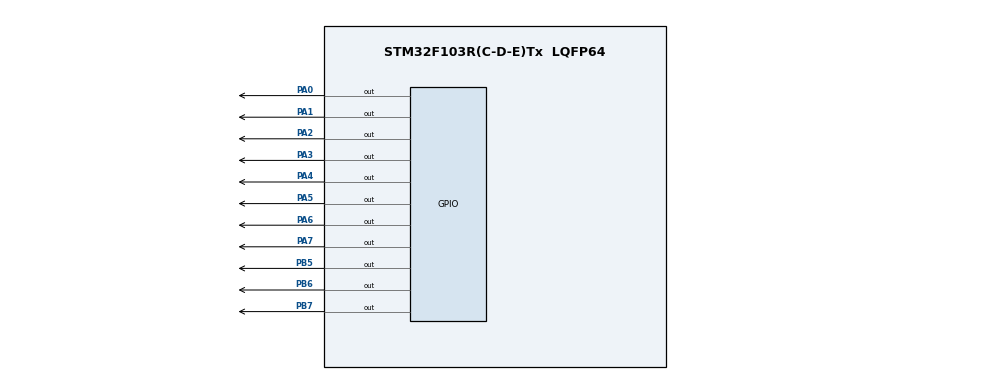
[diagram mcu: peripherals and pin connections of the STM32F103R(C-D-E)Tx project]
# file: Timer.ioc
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Mcu.Family=STM32F1
Mcu.Name=STM32F103R(C-D-E)Tx
Mcu.Package=LQFP64
NVIC.PriorityGroup=NVIC_PRIORITYGROUP_4
NVIC.TIM1_UP_IRQn=true\:1\:0\:true
NVIC.TIM6_IRQn=true\:2\:0\:true
PA0-WKUP.Signal=GPIO_Output
PA1.Signal=GPIO_Output
PA2.Signal=GPIO_Output
PA3.Signal=GPIO_Output
PA4.Signal=GPIO_Output
PA5.Signal=GPIO_Output
PA6.Signal=GPIO_Output
PA7.Signal=GPIO_Output
PB5.Signal=GPIO_Output
PB6.Signal=GPIO_Output
PB7.Signal=GPIO_Output
PD0-OSC_IN.Mode=HSE-External-Oscillator
PD0-OSC_IN.Signal=RCC_OSC_IN
PD1-OSC_OUT.Mode=HSE-External-Oscillator
PD1-OSC_OUT.Signal=RCC_OSC_OUT
ProjectManager.TargetToolchain=EWARM
RCC.APB1Freq_Value=8000000
RCC.APB2Freq_Value=8000000
RCC.SYSCLKSource=RCC_SYSCLKSOURCE_HSE
TIM1.CounterMode=TIM_COUNTERMODE_UP
TIM1.Period=249
TIM1.Prescaler=7999
TIM6.Period=999
TIM6.Prescaler=7999
VP_TIM1_VS_ClockSourceINT.Mode=Internal
VP_TIM6_VS_ClockSourceINT.Mode=Enable_Timer
board=Timer

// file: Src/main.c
/**
  ******************************************************************************
  * File Name          : main.c
  * Description        : Main program body
  ******************************************************************************
  *
  * COPYRIGHT(c) 2016 STMicroelectronics
  *
  * Redistribution and use in source and binary forms, with or without modification,
  * are permitted provided that the following conditions are met:
  *   1. Redistributions of source code must retain the above copyright notice,
  *      this list of conditions and the following disclaimer.
  *   2. Redistributions in binary form must reproduce the above copyright notice,
  *      this list of conditions and the following disclaimer in the documentation
  *      and/or other materials provided with the distribution.
  *   3. Neither the name of STMicroelectronics nor the names of its contributors
  *      may be used to endorse or promote products derived from this software
  *      without specific prior written permission.
  *
  * THIS SOFTWARE IS PROVIDED BY THE COPYRIGHT HOLDERS AND CONTRIBUTORS "AS IS"
  * AND ANY EXPRESS OR IMPLIED WARRANTIES, INCLUDING, BUT NOT LIMITED TO, THE
  * IMPLIED WARRANTIES OF MERCHANTABILITY AND FITNESS FOR A PARTICULAR PURPOSE ARE
  * DISCLAIMED. IN NO EVENT SHALL THE COPYRIGHT HOLDER OR CONTRIBUTORS BE LIABLE
  * FOR ANY DIRECT, INDIRECT, INCIDENTAL, SPECIAL, EXEMPLARY, OR CONSEQUENTIAL
  * DAMAGES (INCLUDING, BUT NOT LIMITED TO, PROCUREMENT OF SUBSTITUTE GOODS OR
  * SERVICES; LOSS OF USE, DATA, OR PROFITS; OR BUSINESS INTERRUPTION) HOWEVER
  * CAUSED AND ON ANY THEORY OF LIABILITY, WHETHER IN CONTRACT, STRICT LIABILITY,
  * OR TORT (INCLUDING NEGLIGENCE OR OTHERWISE) ARISING IN ANY WAY OUT OF THE USE
  * OF THIS SOFTWARE, EVEN IF ADVISED OF THE POSSIBILITY OF SUCH DAMAGE.
  *
  ******************************************************************************
  */
#include "stm32f1xx_hal.h"

/* USER CODE BEGIN Includes */

#include "LCD\lcd.h"
#include <stdio.h>

/* USER CODE END Includes */

TIM_HandleTypeDef htim1;
TIM_HandleTypeDef htim6;

/* USER CODE BEGIN PV */
/* Private variables ---------------------------------------------------------*/

int i,j;
char str[17];

/* USER CODE END PV */

void SystemClock_Config(void);
static void MX_GPIO_Init(void);
static void MX_TIM1_Init(void);
static void MX_TIM6_Init(void);

/* USER CODE BEGIN PFP */
/* Private function prototypes -----------------------------------------------*/

/* USER CODE END PFP */

int main(void)
{

  /* MCU Configuration----------------------------------------------------------*/

  /* Reset of all peripherals, Initializes the Flash interface and the Systick. */
  HAL_Init();

  /* Configure the system clock */
  SystemClock_Config();

  /* Initialize all configured peripherals */
  MX_GPIO_Init();
  MX_TIM1_Init();
  MX_TIM6_Init();

  /* USER CODE BEGIN 2 */

   HAL_TIM_Base_Start_IT(&htim1);
   HAL_TIM_Base_Start_IT(&htim6);

   lcd_init();
   lcd_clear();

  /* USER CODE END 2 */

  /* Infinite loop */
  /* USER CODE BEGIN WHILE */
  while (1)
  {
    sprintf(str,"Timer1=%d",i);

    lcd_gotoxy(0,0);
    lcd_puts(str);

    sprintf(str,"Timer2=%d",j);

    lcd_gotoxy(0,1);
    lcd_puts(str);

  /* USER CODE END WHILE */

  }

}

/** System Clock Configuration
*/
void SystemClock_Config(void)
{

  RCC_OscInitTypeDef RCC_OscInitStruct;
  RCC_ClkInitTypeDef RCC_ClkInitStruct;

  RCC_OscInitStruct.OscillatorType = RCC_OSCILLATORTYPE_HSE;
  RCC_OscInitStruct.HSEState = RCC_HSE_ON;
  RCC_OscInitStruct.PLL.PLLState = RCC_PLL_NONE;
  HAL_RCC_OscConfig(&RCC_OscInitStruct);

  RCC_ClkInitStruct.ClockType = RCC_CLOCKTYPE_SYSCLK;
  RCC_ClkInitStruct.SYSCLKSource = RCC_SYSCLKSOURCE_HSE;
  RCC_ClkInitStruct.AHBCLKDivider = RCC_SYSCLK_DIV1;
  RCC_ClkInitStruct.APB1CLKDivider = RCC_HCLK_DIV1;
  RCC_ClkInitStruct.APB2CLKDivider = RCC_HCLK_DIV1;
  HAL_RCC_ClockConfig(&RCC_ClkInitStruct, FLASH_LATENCY_0);

  HAL_SYSTICK_Config(HAL_RCC_GetHCLKFreq()/1000);

  HAL_SYSTICK_CLKSourceConfig(SYSTICK_CLKSOURCE_HCLK);

  /* SysTick_IRQn interrupt configuration */
  HAL_NVIC_SetPriority(SysTick_IRQn, 0, 0);
}

/* TIM1 init function */
void MX_TIM1_Init(void)
{

  TIM_ClockConfigTypeDef sClockSourceConfig;
  TIM_MasterConfigTypeDef sMasterConfig;

  htim1.Instance = TIM1;
  htim1.Init.Prescaler = 7999;
  htim1.Init.CounterMode = TIM_COUNTERMODE_UP;
  htim1.Init.Period = 249;
  htim1.Init.ClockDivision = TIM_CLOCKDIVISION_DIV1;
  htim1.Init.RepetitionCounter = 0;
  HAL_TIM_Base_Init(&htim1);

  sClockSourceConfig.ClockSource = TIM_CLOCKSOURCE_INTERNAL;
  HAL_TIM_ConfigClockSource(&htim1, &sClockSourceConfig);

  sMasterConfig.MasterOutputTrigger = TIM_TRGO_RESET;
  sMasterConfig.MasterSlaveMode = TIM_MASTERSLAVEMODE_DISABLE;
  HAL_TIMEx_MasterConfigSynchronization(&htim1, &sMasterConfig);

}

/* TIM6 init function */
void MX_TIM6_Init(void)
{

  TIM_MasterConfigTypeDef sMasterConfig;

  htim6.Instance = TIM6;
  htim6.Init.Prescaler = 7999;
  htim6.Init.CounterMode = TIM_COUNTERMODE_UP;
  htim6.Init.Period = 999;
  HAL_TIM_Base_Init(&htim6);

  sMasterConfig.MasterOutputTrigger = TIM_TRGO_RESET;
  sMasterConfig.MasterSlaveMode = TIM_MASTERSLAVEMODE_DISABLE;
  HAL_TIMEx_MasterConfigSynchronization(&htim6, &sMasterConfig);

}

/** Configure pins as
        * Analog
        * Input
        * Output
        * EVENT_OUT
        * EXTI
*/
void MX_GPIO_Init(void)
{

  GPIO_InitTypeDef GPIO_InitStruct;

  /* GPIO Ports Clock Enable */
  __GPIOD_CLK_ENABLE();
  __GPIOA_CLK_ENABLE();
  __GPIOB_CLK_ENABLE();

  /*Configure GPIO pins : PA0 PA1 PA2 PA3
                           PA4 PA5 PA6 PA7 */
  GPIO_InitStruct.Pin = GPIO_PIN_0|GPIO_PIN_1|GPIO_PIN_2|GPIO_PIN_3
                          |GPIO_PIN_4|GPIO_PIN_5|GPIO_PIN_6|GPIO_PIN_7;
  GPIO_InitStruct.Mode = GPIO_MODE_OUTPUT_PP;
  GPIO_InitStruct.Speed = GPIO_SPEED_LOW;
  HAL_GPIO_Init(GPIOA, &GPIO_InitStruct);

  /*Configure GPIO pins : PB5 PB6 PB7 */
  GPIO_InitStruct.Pin = GPIO_PIN_5|GPIO_PIN_6|GPIO_PIN_7;
  GPIO_InitStruct.Mode = GPIO_MODE_OUTPUT_PP;
  GPIO_InitStruct.Speed = GPIO_SPEED_LOW;
  HAL_GPIO_Init(GPIOB, &GPIO_InitStruct);

}

/************************ (C) COPYRIGHT STMicroelectronics *****END OF FILE****/
